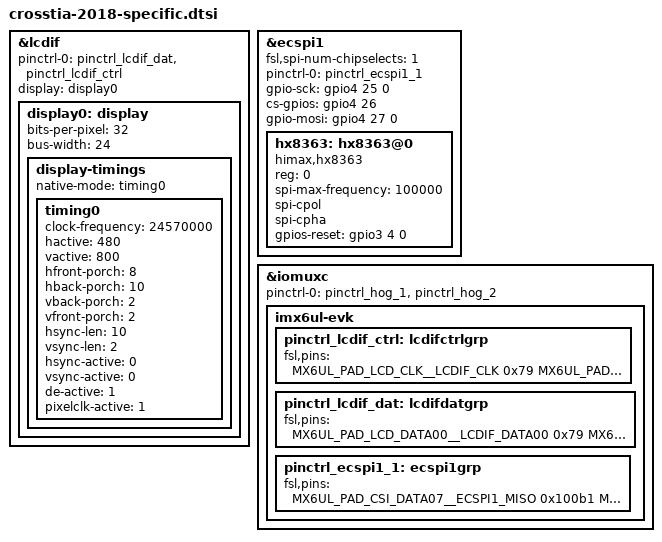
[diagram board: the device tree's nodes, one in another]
/*
 * Copyright (C) 2020 CompeGPS Team S.L.
 * All rights reserved
 *
 */
/dts-v1/;

// TODO: ALL CONFIGURATION IS NOT FOR TIANMA DISPLAY. IT MUST BE ADAPTED.

#include "cross-2018-common.dtsi"

&lcdif {
	pinctrl-names = "default";
	pinctrl-0 = <&pinctrl_lcdif_dat
		     &pinctrl_lcdif_ctrl>;
	display = <&display0>;
	status = "okay";

	display0: display {
		bits-per-pixel = <32>;
		bus-width = <24>;
		
		display-timings {
			native-mode = <&timing0>;
			timing0: timing0 {
				clock-frequency =<24570000>;
				hactive = <480>;
				vactive = <800>;
				hfront-porch = <8>;
				hback-porch = <10>;
				vback-porch = <2>;
				vfront-porch = <2>;
				hsync-len = <10>;
				vsync-len = <2>;
				hsync-active = <0>;
				vsync-active = <0>;
				de-active = <1>;
				pixelclk-active = <1>;
			};
		};
	};
};

&ecspi1 {
	fsl,spi-num-chipselects = <1>;
	pinctrl-names = "default";
	pinctrl-0 = <&pinctrl_ecspi1_1>;
	status = "okay";
	gpio-sck = <&gpio4 25 0>;
	cs-gpios = <&gpio4 26 0>;
	gpio-mosi = <&gpio4 27 0>;
	//gpio-miso = <&gpio4 28 0>; // not connected - not used
	//num-chipselects = <1>; // unknown

	hx8363: hx8363@0 {
		compatible = "himax,hx8363";
		reg = <0>;
		spi-max-frequency = <100000>;
		spi-cpol;
		spi-cpha;
		gpios-reset = <&gpio3 4 0>;
	};
};


&iomuxc {
	pinctrl-names = "default";
	pinctrl-0 = <&pinctrl_hog_1 &pinctrl_hog_2>;
	imx6ul-evk {
		pinctrl_lcdif_ctrl: lcdifctrlgrp {
			fsl,pins = <
				MX6UL_PAD_LCD_CLK__LCDIF_CLK		0x79
				MX6UL_PAD_LCD_ENABLE__LCDIF_ENABLE	0x79
				MX6UL_PAD_LCD_HSYNC__LCDIF_HSYNC	0x79
				MX6UL_PAD_LCD_VSYNC__LCDIF_VSYNC	0x79
				MX6UL_PAD_LCD_RESET__GPIO3_IO04		0x1b0b1
			>;
		};

		pinctrl_lcdif_dat: lcdifdatgrp {
			fsl,pins = <
				MX6UL_PAD_LCD_DATA00__LCDIF_DATA00	0x79
				MX6UL_PAD_LCD_DATA01__LCDIF_DATA01	0x79
				MX6UL_PAD_LCD_DATA02__LCDIF_DATA02	0x79
				MX6UL_PAD_LCD_DATA03__LCDIF_DATA03	0x79
				MX6UL_PAD_LCD_DATA04__LCDIF_DATA04	0x79
				MX6UL_PAD_LCD_DATA05__LCDIF_DATA05	0x79
				MX6UL_PAD_LCD_DATA06__LCDIF_DATA06	0x79
				MX6UL_PAD_LCD_DATA07__LCDIF_DATA07	0x79
				MX6UL_PAD_LCD_DATA08__LCDIF_DATA08	0x79
				MX6UL_PAD_LCD_DATA09__LCDIF_DATA09	0x79
				MX6UL_PAD_LCD_DATA10__LCDIF_DATA10	0x79
				MX6UL_PAD_LCD_DATA11__LCDIF_DATA11	0x79
				MX6UL_PAD_LCD_DATA12__LCDIF_DATA12	0x79
				MX6UL_PAD_LCD_DATA13__LCDIF_DATA13	0x79
				MX6UL_PAD_LCD_DATA14__LCDIF_DATA14	0x79
				MX6UL_PAD_LCD_DATA15__LCDIF_DATA15	0x79
				MX6UL_PAD_LCD_DATA16__LCDIF_DATA16	0x79
				MX6UL_PAD_LCD_DATA17__LCDIF_DATA17	0x79
				MX6UL_PAD_LCD_DATA18__LCDIF_DATA18	0x79
				MX6UL_PAD_LCD_DATA19__LCDIF_DATA19	0x79
				MX6UL_PAD_LCD_DATA20__LCDIF_DATA20	0x79
				MX6UL_PAD_LCD_DATA21__LCDIF_DATA21	0x79
				MX6UL_PAD_LCD_DATA22__LCDIF_DATA22	0x79
				MX6UL_PAD_LCD_DATA23__LCDIF_DATA23	0x79
			>;
		};

		pinctrl_ecspi1_1: ecspi1grp {
			fsl,pins = <
				MX6UL_PAD_CSI_DATA07__ECSPI1_MISO       0x100b1
				MX6UL_PAD_CSI_DATA06__ECSPI1_MOSI       0x100b1
				MX6UL_PAD_CSI_DATA04__ECSPI1_SCLK       0x100b1
				MX6UL_PAD_CSI_DATA05__GPIO4_IO26        0x100b1				
			>;
		};
	};
};
